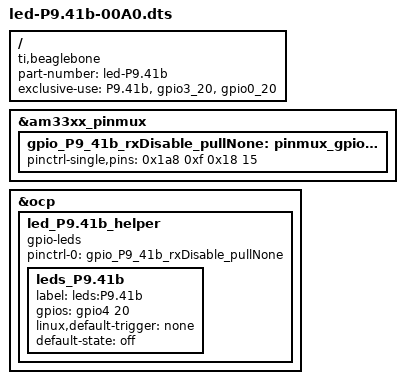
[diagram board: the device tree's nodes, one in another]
/*
* Easy gpio mux control of "P9.41b" ("gpio3_20", "gpio0_20")
*/
/dts-v1/;
/plugin/;

/ {
	compatible = "ti,beaglebone", "ti,beaglebone-black";

	/* identification */
	part-number = "led-P9.41b";
	/* version = "00A0"; */

	/* state the resources this cape uses */
	exclusive-use =
		/* the pin header uses */
		"P9.41b",

		/* the hardware IP uses */
		"gpio3_20", "gpio0_20";
	
	
	/* rxDisable_pullNone state */
	fragment@0 {
		target = <&am33xx_pinmux>;
		__overlay__ {
			gpio_P9_41b_rxDisable_pullNone: pinmux_gpio_P9.41b_rxDisable_pullNone {
				pinctrl-single,pins = <
					0x1a8 0xf	0x18 15
				>;
			};
		};
	};

	fragment@1 {
		target = <&ocp>;
		__overlay__ {
			led_P9.41b_helper {
				compatible = "gpio-leds";
				pinctrl-names = "default";
				pinctrl-0 = <&gpio_P9_41b_rxDisable_pullNone>;
				
				leds_P9.41b {
					label = "leds:P9.41b";
					gpios = <&gpio4 20 0>;
					linux,default-trigger = "none";
					default-state = "off";
				};
			};
			
		};
	};

};
